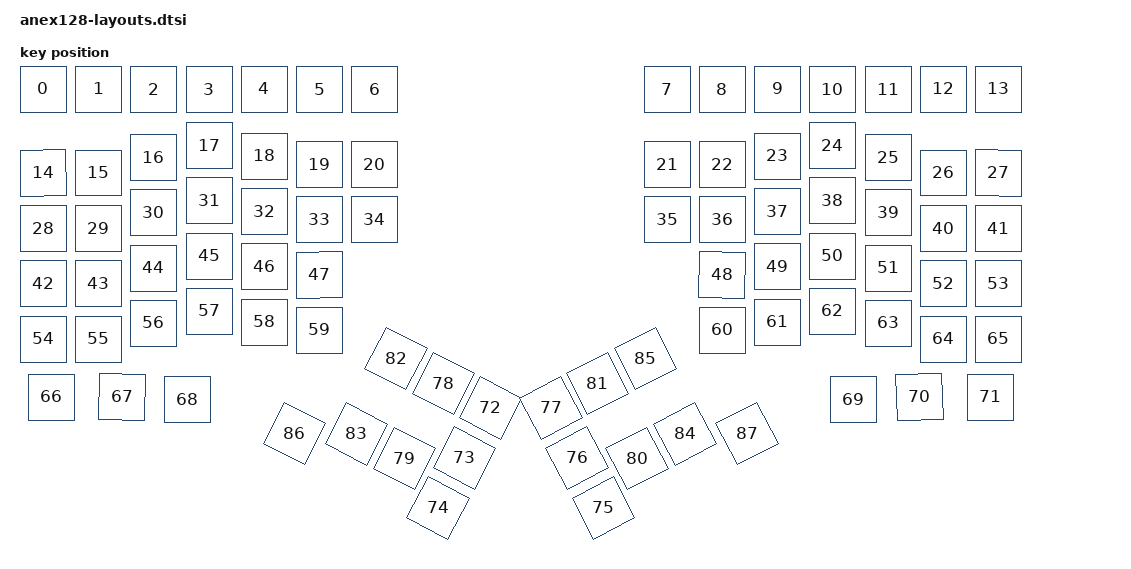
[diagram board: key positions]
#include <physical_layouts.dtsi>

/ {
    default_layout: physical_layout_0 {
        compatible = "zmk,physical-layout";
        display-name = "Default Layout";
        transform = <&default_transform>;

        keys
            = <&key_physical_attrs 100 100 0 0 0 0 0>
            , <&key_physical_attrs 100 100 111 0 0 0 0>
            , <&key_physical_attrs 100 100 221 1 0 0 0>
            , <&key_physical_attrs 100 100 332 1 0 0 0>
            , <&key_physical_attrs 100 100 442 0 0 0 0>
            , <&key_physical_attrs 100 100 553 1 0 0 0>
            , <&key_physical_attrs 100 100 663 1 0 0 0>
            , <&key_physical_attrs 100 100 1248 1 0 0 0>
            , <&key_physical_attrs 100 100 1358 1 0 0 0>
            , <&key_physical_attrs 100 100 1469 0 0 0 0>
            , <&key_physical_attrs 100 100 1579 1 0 0 0>
            , <&key_physical_attrs 100 100 1690 1 0 0 0>
            , <&key_physical_attrs 100 100 1800 0 0 0 0>
            , <&key_physical_attrs 100 100 1911 0 0 0 0>
            , <&key_physical_attrs 100 100 0 168 (-2) 50 218>
            , <&key_physical_attrs 100 100 111 168 0 0 0>
            , <&key_physical_attrs 100 100 221 137 0 0 0>
            , <&key_physical_attrs 100 100 332 113 0 0 0>
            , <&key_physical_attrs 100 100 442 134 0 0 0>
            , <&key_physical_attrs 100 100 553 151 0 0 0>
            , <&key_physical_attrs 100 100 663 151 0 0 0>
            , <&key_physical_attrs 100 100 1248 151 0 0 0>
            , <&key_physical_attrs 100 100 1358 151 0 0 0>
            , <&key_physical_attrs 100 100 1469 134 0 0 0>
            , <&key_physical_attrs 100 100 1579 113 0 0 0>
            , <&key_physical_attrs 100 100 1690 137 0 0 0>
            , <&key_physical_attrs 100 100 1800 168 0 0 0>
            , <&key_physical_attrs 100 100 1911 168 2 1961 218>
            , <&key_physical_attrs 100 100 0 279 0 0 0>
            , <&key_physical_attrs 100 100 111 279 0 0 0>
            , <&key_physical_attrs 100 100 221 247 0 0 0>
            , <&key_physical_attrs 100 100 332 223 0 0 0>
            , <&key_physical_attrs 100 100 442 245 0 0 0>
            , <&key_physical_attrs 100 100 553 261 0 0 0>
            , <&key_physical_attrs 100 100 663 261 0 0 0>
            , <&key_physical_attrs 100 100 1248 261 0 0 0>
            , <&key_physical_attrs 100 100 1358 261 0 0 0>
            , <&key_physical_attrs 100 100 1469 245 0 0 0>
            , <&key_physical_attrs 100 100 1579 223 0 0 0>
            , <&key_physical_attrs 100 100 1690 247 0 0 0>
            , <&key_physical_attrs 100 100 1800 279 0 0 0>
            , <&key_physical_attrs 100 100 1911 279 0 0 0>
            , <&key_physical_attrs 100 100 0 389 0 0 0>
            , <&key_physical_attrs 100 100 111 389 0 0 0>
            , <&key_physical_attrs 100 100 221 358 0 0 0>
            , <&key_physical_attrs 100 100 332 334 0 0 0>
            , <&key_physical_attrs 100 100 442 355 0 0 0>
            , <&key_physical_attrs 100 100 553 372 (-4) 603 422>
            , <&key_physical_attrs 100 100 1358 372 4 1408 422>
            , <&key_physical_attrs 100 100 1469 355 0 0 0>
            , <&key_physical_attrs 100 100 1579 334 0 0 0>
            , <&key_physical_attrs 100 100 1690 358 0 0 0>
            , <&key_physical_attrs 100 100 1800 389 0 0 0>
            , <&key_physical_attrs 100 100 1911 389 0 0 0>
            , <&key_physical_attrs 100 100 0 500 0 0 0>
            , <&key_physical_attrs 100 100 111 500 0 0 0>
            , <&key_physical_attrs 100 100 221 468 0 0 0>
            , <&key_physical_attrs 100 100 332 444 0 0 0>
            , <&key_physical_attrs 100 100 442 466 0 0 0>
            , <&key_physical_attrs 100 100 553 482 0 0 0>
            , <&key_physical_attrs 100 100 1358 482 0 0 0>
            , <&key_physical_attrs 100 100 1469 466 0 0 0>
            , <&key_physical_attrs 100 100 1579 444 0 0 0>
            , <&key_physical_attrs 100 100 1690 468 0 0 0>
            , <&key_physical_attrs 100 100 1800 500 0 0 0>
            , <&key_physical_attrs 100 100 1911 500 0 0 0>
            , <&key_physical_attrs 100 100 17 616 0 0 0>
            , <&key_physical_attrs 100 100 158 616 200 208 666>
            , <&key_physical_attrs 100 100 289 621 100 339 671>
            , <&key_physical_attrs 100 100 1621 621 (-100) 1671 671>
            , <&key_physical_attrs 100 100 1753 616 (-200) 1803 666>
            , <&key_physical_attrs 100 100 1894 616 0 0 0>
            , <&key_physical_attrs 100 100 895 638 11770 945 688>
            , <&key_physical_attrs 100 100 843 738 11770 893 788>
            , <&key_physical_attrs 100 100 790 838 11770 840 888>
            , <&key_physical_attrs 100 100 1121 838 (-11770) 1171 888>
            , <&key_physical_attrs 100 100 1068 738 (-11770) 1118 788>
            , <&key_physical_attrs 100 100 1016 638 (-11770) 1066 688>
            , <&key_physical_attrs 100 100 801 589 11770 851 639>
            , <&key_physical_attrs 100 100 723 739 11770 773 789>
            , <&key_physical_attrs 100 100 1188 739 (-11770) 1238 789>
            , <&key_physical_attrs 100 100 1109 589 (-11770) 1159 639>
            , <&key_physical_attrs 100 100 706 539 2753 756 589>
            , <&key_physical_attrs 100 100 627 690 11770 677 740>
            , <&key_physical_attrs 100 100 1284 690 (-11770) 1334 740>
            , <&key_physical_attrs 100 100 1205 539 (-2753) 1255 589>
            , <&key_physical_attrs 100 100 503 689 11770 553 739>
            , <&key_physical_attrs 100 100 1408 689 (-11770) 1458 739>
            ;
    };
};
